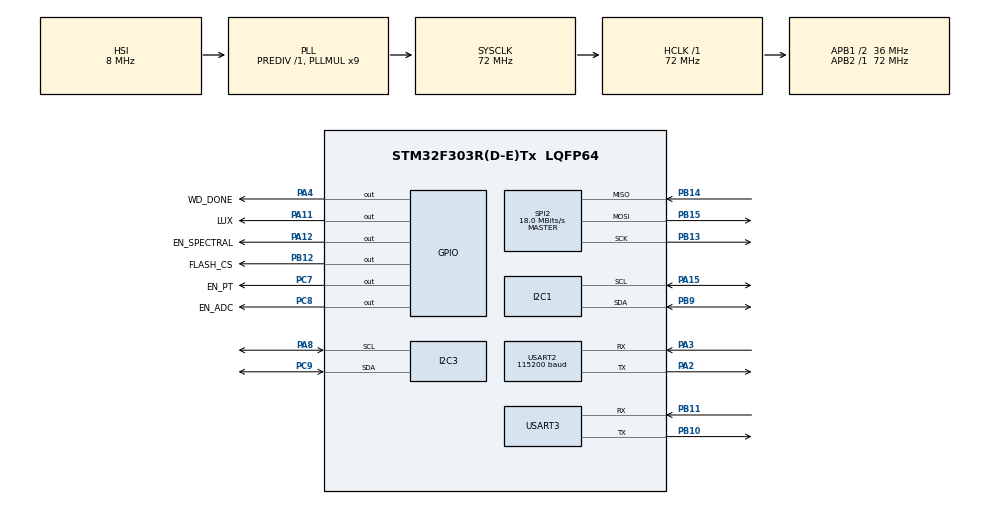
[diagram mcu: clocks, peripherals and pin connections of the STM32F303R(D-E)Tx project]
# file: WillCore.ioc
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Dma.Request0=USART2_RX
Dma.Request1=USART3_RX
Dma.USART2_RX.0.Direction=DMA_PERIPH_TO_MEMORY
Dma.USART2_RX.0.Instance=DMA1_Channel6
Dma.USART2_RX.0.MemDataAlignment=DMA_MDATAALIGN_BYTE
Dma.USART2_RX.0.MemInc=DMA_MINC_ENABLE
Dma.USART2_RX.0.Mode=DMA_NORMAL
Dma.USART2_RX.0.PeriphDataAlignment=DMA_PDATAALIGN_BYTE
Dma.USART2_RX.0.PeriphInc=DMA_PINC_DISABLE
Dma.USART2_RX.0.Priority=DMA_PRIORITY_LOW
Dma.USART3_RX.1.Direction=DMA_PERIPH_TO_MEMORY
Dma.USART3_RX.1.Instance=DMA1_Channel3
Dma.USART3_RX.1.MemDataAlignment=DMA_MDATAALIGN_BYTE
Dma.USART3_RX.1.MemInc=DMA_MINC_ENABLE
Dma.USART3_RX.1.Mode=DMA_NORMAL
Dma.USART3_RX.1.PeriphDataAlignment=DMA_PDATAALIGN_BYTE
Dma.USART3_RX.1.PeriphInc=DMA_PINC_DISABLE
Dma.USART3_RX.1.Priority=DMA_PRIORITY_LOW
I2C1.Timing=0x00201D2B
I2C3.Timing=0x00201D2B
Mcu.Family=STM32F3
Mcu.Name=STM32F303R(D-E)Tx
Mcu.Package=LQFP64
NVIC.DMA1_Channel3_IRQn=true\:1\:0\:true\:false\:true\:false\:true\:true
NVIC.DMA1_Channel6_IRQn=true\:2\:0\:true\:false\:true\:false\:true\:true
NVIC.PriorityGroup=NVIC_PRIORITYGROUP_4
PA0.Mode=SYS_WakeUp0
PA0.Signal=SYS_WKUP1
PA11.GPIO_Label=LUX
PA11.Signal=GPIO_Output
PA12.GPIO_Label=EN_SPECTRAL
PA12.Signal=GPIO_Output
PA15.Mode=I2C
PA15.Signal=I2C1_SCL
PA2.Mode=Asynchronous
PA2.Signal=USART2_TX
PA3.Mode=Asynchronous
PA3.Signal=USART2_RX
PA4.GPIO_Label=WD_DONE
PA4.GPIO_PuPd=GPIO_PULLDOWN
PA4.Signal=GPIO_Output
PA8.Mode=I2C
PA8.Signal=I2C3_SCL
PB10.Mode=Asynchronous
PB10.Signal=USART3_TX
PB11.Mode=Asynchronous
PB11.Signal=USART3_RX
PB12.GPIO_Label=FLASH_CS
PB12.GPIO_PuPd=GPIO_PULLUP
PB12.Signal=GPIO_Output
PB13.Mode=Full_Duplex_Master
PB13.Signal=SPI2_SCK
PB14.Mode=Full_Duplex_Master
PB14.Signal=SPI2_MISO
PB15.Mode=Full_Duplex_Master
PB15.Signal=SPI2_MOSI
PB9.Mode=I2C
PB9.Signal=I2C1_SDA
PC7.GPIO_Label=EN_PT
PC7.Signal=GPIO_Output
PC8.GPIO_Label=EN_ADC
PC8.Signal=GPIO_Output
PC9.Mode=I2C
PC9.Signal=I2C3_SDA
ProjectManager.HeapSize=0x200
ProjectManager.StackSize=0x400
ProjectManager.TargetToolchain=STM32CubeIDE
RCC.AHBFreq_Value=72000000
RCC.APB1CLKDivider=RCC_HCLK_DIV2
RCC.APB1Freq_Value=36000000
RCC.APB1TimFreq_Value=72000000
RCC.APB2Freq_Value=72000000
RCC.APB2TimFreq_Value=72000000
RCC.CortexFreq_Value=72000000
RCC.HCLKFreq_Value=72000000
RCC.HSE_VALUE=8000000
RCC.HSI_VALUE=8000000
RCC.LSE_VALUE=32768
RCC.PLLMUL=RCC_PLL_MUL9
RCC.SYSCLKFreq_VALUE=72000000
RCC.SYSCLKSourceVirtual=RCC_SYSCLKSOURCE_PLLCLK
RCC.USBFreq_Value=72000000
SPI2.CalculateBaudRate=18.0 MBits/s
SPI2.DataSize=SPI_DATASIZE_8BIT
SPI2.Direction=SPI_DIRECTION_2LINES
SPI2.Mode=SPI_MODE_MASTER
SPI2.VirtualType=VM_MASTER
USART2.BaudRate=115200
USART2.VirtualMode-Asynchronous=VM_ASYNC
USART3.VirtualMode-Asynchronous=VM_ASYNC
board=custom

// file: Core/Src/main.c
/* USER CODE BEGIN Header */
/**
  ******************************************************************************
  * @file           : main.c
  * @brief          : Main program body
  ******************************************************************************
  * @attention
  *
  * Copyright (c) 2025 STMicroelectronics.
  * All rights reserved.
  *
  * This software is licensed under terms that can be found in the LICENSE file
  * in the root directory of this software component.
  * If no LICENSE file comes with this software, it is provided AS-IS.
  *
  ******************************************************************************
  */
/* USER CODE END Header */
#include "main.h"
#include "dma.h"
#include "i2c.h"
#include "spi.h"
#include "usart.h"
#include "gpio.h"

void SystemClock_Config(void);

int main(void)
{

  /* MCU Configuration--------------------------------------------------------*/

  /* Reset of all peripherals, Initializes the Flash interface and the Systick. */
  HAL_Init();

  /* Configure the system clock */
  SystemClock_Config();

  /* Initialize all configured peripherals */
  MX_GPIO_Init();
  MX_DMA_Init();
  MX_I2C1_Init();
  MX_I2C3_Init();
  MX_SPI2_Init();
  MX_USART2_UART_Init();
  MX_USART3_UART_Init();
  /* USER CODE BEGIN 2 */
  Setup();
  /* USER CODE END 2 */

  /* Infinite loop */
  /* USER CODE BEGIN WHILE */
  while (1)
  {
	  Loop();
    /* USER CODE END WHILE */

  }
}

void SystemClock_Config(void)
{
  RCC_OscInitTypeDef RCC_OscInitStruct = {0};
  RCC_ClkInitTypeDef RCC_ClkInitStruct = {0};
  RCC_PeriphCLKInitTypeDef PeriphClkInit = {0};

  /** Initializes the RCC Oscillators according to the specified parameters
  * in the RCC_OscInitTypeDef structure.
  */
  RCC_OscInitStruct.OscillatorType = RCC_OSCILLATORTYPE_HSI;
  RCC_OscInitStruct.HSIState = RCC_HSI_ON;
  RCC_OscInitStruct.HSICalibrationValue = RCC_HSICALIBRATION_DEFAULT;
  RCC_OscInitStruct.PLL.PLLState = RCC_PLL_ON;
  RCC_OscInitStruct.PLL.PLLSource = RCC_PLLSOURCE_HSI;
  RCC_OscInitStruct.PLL.PLLMUL = RCC_PLL_MUL9;
  RCC_OscInitStruct.PLL.PREDIV = RCC_PREDIV_DIV1;
  if (HAL_RCC_OscConfig(&RCC_OscInitStruct) != HAL_OK)
  {
    Error_Handler();
  }

  /** Initializes the CPU, AHB and APB buses clocks
  */
  RCC_ClkInitStruct.ClockType = RCC_CLOCKTYPE_HCLK|RCC_CLOCKTYPE_SYSCLK
                              |RCC_CLOCKTYPE_PCLK1|RCC_CLOCKTYPE_PCLK2;
  RCC_ClkInitStruct.SYSCLKSource = RCC_SYSCLKSOURCE_PLLCLK;
  RCC_ClkInitStruct.AHBCLKDivider = RCC_SYSCLK_DIV1;
  RCC_ClkInitStruct.APB1CLKDivider = RCC_HCLK_DIV2;
  RCC_ClkInitStruct.APB2CLKDivider = RCC_HCLK_DIV1;

  if (HAL_RCC_ClockConfig(&RCC_ClkInitStruct, FLASH_LATENCY_2) != HAL_OK)
  {
    Error_Handler();
  }
  PeriphClkInit.PeriphClockSelection = RCC_PERIPHCLK_USART2|RCC_PERIPHCLK_USART3
                              |RCC_PERIPHCLK_I2C1|RCC_PERIPHCLK_I2C3;
  PeriphClkInit.Usart2ClockSelection = RCC_USART2CLKSOURCE_PCLK1;
  PeriphClkInit.Usart3ClockSelection = RCC_USART3CLKSOURCE_PCLK1;
  PeriphClkInit.I2c1ClockSelection = RCC_I2C1CLKSOURCE_HSI;
  PeriphClkInit.I2c3ClockSelection = RCC_I2C3CLKSOURCE_HSI;
  if (HAL_RCCEx_PeriphCLKConfig(&PeriphClkInit) != HAL_OK)
  {
    Error_Handler();
  }
}

void Error_Handler(void)
{
  __disable_irq();
  while (1)
  {
  }
}
